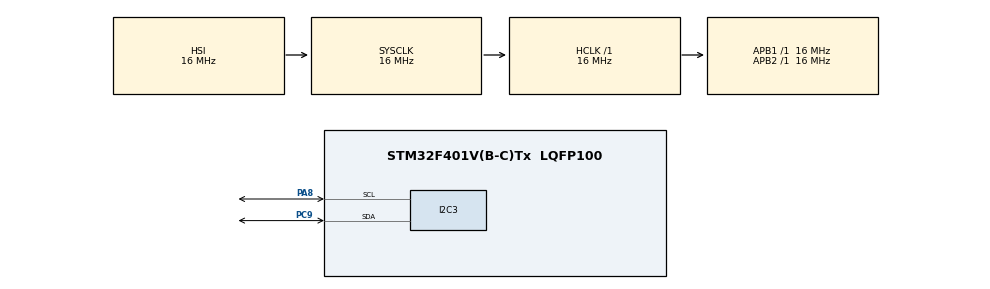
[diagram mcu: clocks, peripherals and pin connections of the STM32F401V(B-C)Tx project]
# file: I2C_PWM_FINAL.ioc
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Mcu.Family=STM32F4
Mcu.Name=STM32F401V(B-C)Tx
Mcu.Package=LQFP100
NVIC.PriorityGroup=NVIC_PRIORITYGROUP_4
PA8.Mode=I2C
PA8.Signal=I2C3_SCL
PC9.Mode=I2C
PC9.Signal=I2C3_SDA
ProjectManager.HeapSize=0x200
ProjectManager.StackSize=0x400
ProjectManager.TargetToolchain=MDK-ARM V5
RCC.AHBFreq_Value=16000000
RCC.APB1Freq_Value=16000000
RCC.APB2Freq_Value=16000000
RCC.CortexFreq_Value=16000000
RCC.HSE_VALUE=25000000
RCC.HSI_VALUE=16000000
RCC.LSE_VALUE=32768
RCC.SYSCLKFreq_VALUE=16000000
RCC.VCOOutputFreq_Value=192000000
board=custom

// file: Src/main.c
/* USER CODE BEGIN Header */
/**
  ******************************************************************************
  * @file           : main.c
  * @brief          : Main program body
  ******************************************************************************
  ** This notice applies to any and all portions of this file
  * that are not between comment pairs USER CODE BEGIN and
  * USER CODE END. Other portions of this file, whether
  * inserted by the user or by software development tools
  * are owned by their respective copyright owners.
  *
  * COPYRIGHT(c) 2019 STMicroelectronics
  *
  * Redistribution and use in source and binary forms, with or without modification,
  * are permitted provided that the following conditions are met:
  *   1. Redistributions of source code must retain the above copyright notice,
  *      this list of conditions and the following disclaimer.
  *   2. Redistributions in binary form must reproduce the above copyright notice,
  *      this list of conditions and the following disclaimer in the documentation
  *      and/or other materials provided with the distribution.
  *   3. Neither the name of STMicroelectronics nor the names of its contributors
  *      may be used to endorse or promote products derived from this software
  *      without specific prior written permission.
  *
  * THIS SOFTWARE IS PROVIDED BY THE COPYRIGHT HOLDERS AND CONTRIBUTORS "AS IS"
  * AND ANY EXPRESS OR IMPLIED WARRANTIES, INCLUDING, BUT NOT LIMITED TO, THE
  * IMPLIED WARRANTIES OF MERCHANTABILITY AND FITNESS FOR A PARTICULAR PURPOSE ARE
  * DISCLAIMED. IN NO EVENT SHALL THE COPYRIGHT HOLDER OR CONTRIBUTORS BE LIABLE
  * FOR ANY DIRECT, INDIRECT, INCIDENTAL, SPECIAL, EXEMPLARY, OR CONSEQUENTIAL
  * DAMAGES (INCLUDING, BUT NOT LIMITED TO, PROCUREMENT OF SUBSTITUTE GOODS OR
  * SERVICES; LOSS OF USE, DATA, OR PROFITS; OR BUSINESS INTERRUPTION) HOWEVER
  * CAUSED AND ON ANY THEORY OF LIABILITY, WHETHER IN CONTRACT, STRICT LIABILITY,
  * OR TORT (INCLUDING NEGLIGENCE OR OTHERWISE) ARISING IN ANY WAY OUT OF THE USE
  * OF THIS SOFTWARE, EVEN IF ADVISED OF THE POSSIBILITY OF SUCH DAMAGE.
  *
  ******************************************************************************
  */
/* USER CODE END Header */

#include "main.h"

I2C_HandleTypeDef hi2c3;

void SystemClock_Config(void);
static void MX_GPIO_Init(void);
static void MX_I2C3_Init(void);

/* USER CODE BEGIN 0 */
uint8_t Motor1GoF[2] = {0x01,0x4B};
uint8_t Motor1GoB[2] = {0x01,0x19};
uint8_t Motor1Stop[2] = {0x01,0x32};

uint8_t Motor2GoF[2] = {0x02, 0x4B};
uint8_t Motor2GoB[2] = {0x02, 0x19};
uint8_t Motor2Stop[2] = {0x02, 0x32};

uint8_t Motor3GoF[2] = {0x04, 0x4B};
uint8_t Motor3GoB[2] = {0x04, 0x19};
uint8_t Motor3Stop[2] = {0x04, 0x32};

uint8_t Motor4GoF[2] = {0x08, 0x4B};
uint8_t Motor4GoB[2] = {0x08, 0x19};
uint8_t Motor4Stop[2] = {0x08, 0x32};

uint8_t Motor5GoF[2] = {0x10, 0x4B};
uint8_t Motor5GoB[2] = {0x10, 0x19};
uint8_t Motor5Stop[2] = {0x10, 0x32};

uint8_t Motor6GoF[2] = {0x20, 0x4B};
uint8_t Motor6GoB[2] = {0x20, 0x19};
uint8_t Motor6Stop[2] = {0x20, 0x32};

uint8_t Motor7GoF[2] = {0x40, 0x4B};
uint8_t Motor7GoB[2] = {0x40, 0x19};
uint8_t Motor7Stop[2] = {0x40, 0x32};

uint8_t Motor8GoF[2] = {0x80, 0x4B};
uint8_t Motor8GoB[2] = {0x80, 0x19};
uint8_t Motor8Stop[2] = {0x80, 0x32};
/* USER CODE END 0 */

int main(void)
{

  /* MCU Configuration--------------------------------------------------------*/

  /* Reset of all peripherals, Initializes the Flash interface and the Systick. */
  HAL_Init();

  /* Configure the system clock */
  SystemClock_Config();

  /* Initialize all configured peripherals */
  MX_GPIO_Init();
  MX_I2C3_Init();
  /* USER CODE BEGIN 2 */

		HAL_I2C_Master_Transmit(&hi2c3, 0x10, Motor1GoF, 2, 1);
		HAL_Delay(2000);

		HAL_I2C_Master_Transmit(&hi2c3, 0x10, Motor1Stop, 2, 1);
		HAL_Delay(2000);

		HAL_I2C_Master_Transmit(&hi2c3, 0x10, Motor1GoB, 2, 1);
		HAL_Delay(2000);

		HAL_I2C_Master_Transmit(&hi2c3, 0x10, Motor2GoF, 2, 1);
		HAL_Delay(2000);

		HAL_I2C_Master_Transmit(&hi2c3, 0x10, Motor2Stop, 2, 1);
		HAL_Delay(2000);

		HAL_I2C_Master_Transmit(&hi2c3, 0x10, Motor2GoB, 2, 1);
		HAL_Delay(2000);

		HAL_I2C_Master_Transmit(&hi2c3, 0x10, Motor3GoF, 2, 1);
		HAL_Delay(2000);

		HAL_I2C_Master_Transmit(&hi2c3, 0x10, Motor3Stop, 2, 1);
		HAL_Delay(2000);

		HAL_I2C_Master_Transmit(&hi2c3, 0x10, Motor3GoB, 2, 1);
		HAL_Delay(2000);

	  HAL_I2C_Master_Transmit(&hi2c3, 0x10, Motor4GoF, 2, 1);
		HAL_Delay(2000);

		HAL_I2C_Master_Transmit(&hi2c3, 0x10, Motor4Stop, 2, 1);
		HAL_Delay(2000);

		HAL_I2C_Master_Transmit(&hi2c3, 0x10, Motor4GoB, 2, 1);
		HAL_Delay(2000);

		HAL_I2C_Master_Transmit(&hi2c3, 0x10, Motor5GoF, 2, 1);
		HAL_Delay(2000);

		HAL_I2C_Master_Transmit(&hi2c3, 0x10, Motor5Stop, 2, 1);
		HAL_Delay(2000);

		HAL_I2C_Master_Transmit(&hi2c3, 0x10, Motor5GoB, 2, 1);
		HAL_Delay(2000);

		HAL_I2C_Master_Transmit(&hi2c3, 0x10, Motor6GoF, 2, 1);
		HAL_Delay(2000);

		HAL_I2C_Master_Transmit(&hi2c3, 0x10, Motor6Stop, 2, 1);
		HAL_Delay(2000);

		HAL_I2C_Master_Transmit(&hi2c3, 0x10, Motor6GoB, 2, 1);
		HAL_Delay(2000);

  /* USER CODE END 2 */

  /* Infinite loop */
  while (1)
  {

    /* USER CODE BEGIN 3 */

		/*HAL_I2C_Master_Transmit(&hi2c3, 0x10, Motor1GoF, 2, 1);
		HAL_Delay(1000);

		HAL_I2C_Master_Transmit(&hi2c3, 0x10, Motor1Stop, 2, 1);
		HAL_Delay(2500);

		HAL_Delay(1000);
		HAL_I2C_Master_Transmit(&hi2c3, 0x10, Motor1GoB, 2, 1);

		HAL_I2C_Master_Transmit(&hi2c3, 0x10, Motor2GoF, 2, 1);
		HAL_Delay(1000);

		HAL_I2C_Master_Transmit(&hi2c3, 0x10, Motor2Stop, 2, 1);
		HAL_Delay(1000);

		HAL_I2C_Master_Transmit(&hi2c3, 0x10, Motor2GoB, 2, 1);
		HAL_Delay(1000);*/

  }
  /* USER CODE END 3 */
}

void SystemClock_Config(void)
{
  RCC_OscInitTypeDef RCC_OscInitStruct = {0};
  RCC_ClkInitTypeDef RCC_ClkInitStruct = {0};

  /**Configure the main internal regulator output voltage
  */
  __HAL_RCC_PWR_CLK_ENABLE();
  __HAL_PWR_VOLTAGESCALING_CONFIG(PWR_REGULATOR_VOLTAGE_SCALE2);
  /**Initializes the CPU, AHB and APB busses clocks
  */
  RCC_OscInitStruct.OscillatorType = RCC_OSCILLATORTYPE_HSI;
  RCC_OscInitStruct.HSIState = RCC_HSI_ON;
  RCC_OscInitStruct.HSICalibrationValue = RCC_HSICALIBRATION_DEFAULT;
  RCC_OscInitStruct.PLL.PLLState = RCC_PLL_NONE;
  if (HAL_RCC_OscConfig(&RCC_OscInitStruct) != HAL_OK)
  {
    Error_Handler();
  }
  /**Initializes the CPU, AHB and APB busses clocks
  */
  RCC_ClkInitStruct.ClockType = RCC_CLOCKTYPE_HCLK|RCC_CLOCKTYPE_SYSCLK
                              |RCC_CLOCKTYPE_PCLK1|RCC_CLOCKTYPE_PCLK2;
  RCC_ClkInitStruct.SYSCLKSource = RCC_SYSCLKSOURCE_HSI;
  RCC_ClkInitStruct.AHBCLKDivider = RCC_SYSCLK_DIV1;
  RCC_ClkInitStruct.APB1CLKDivider = RCC_HCLK_DIV1;
  RCC_ClkInitStruct.APB2CLKDivider = RCC_HCLK_DIV1;

  if (HAL_RCC_ClockConfig(&RCC_ClkInitStruct, FLASH_LATENCY_0) != HAL_OK)
  {
    Error_Handler();
  }
}

static void MX_I2C3_Init(void)
{

  hi2c3.Instance = I2C3;
  hi2c3.Init.ClockSpeed = 100000;
  hi2c3.Init.DutyCycle = I2C_DUTYCYCLE_2;
  hi2c3.Init.OwnAddress1 = 0;
  hi2c3.Init.AddressingMode = I2C_ADDRESSINGMODE_7BIT;
  hi2c3.Init.DualAddressMode = I2C_DUALADDRESS_DISABLE;
  hi2c3.Init.OwnAddress2 = 0;
  hi2c3.Init.GeneralCallMode = I2C_GENERALCALL_DISABLE;
  hi2c3.Init.NoStretchMode = I2C_NOSTRETCH_DISABLE;
  if (HAL_I2C_Init(&hi2c3) != HAL_OK)
  {
    Error_Handler();
  }

}

static void MX_GPIO_Init(void)
{

  /* GPIO Ports Clock Enable */
  __HAL_RCC_GPIOC_CLK_ENABLE();
  __HAL_RCC_GPIOA_CLK_ENABLE();

}

void Error_Handler(void)
{
}

/************************ (C) COPYRIGHT STMicroelectronics *****END OF FILE****/
